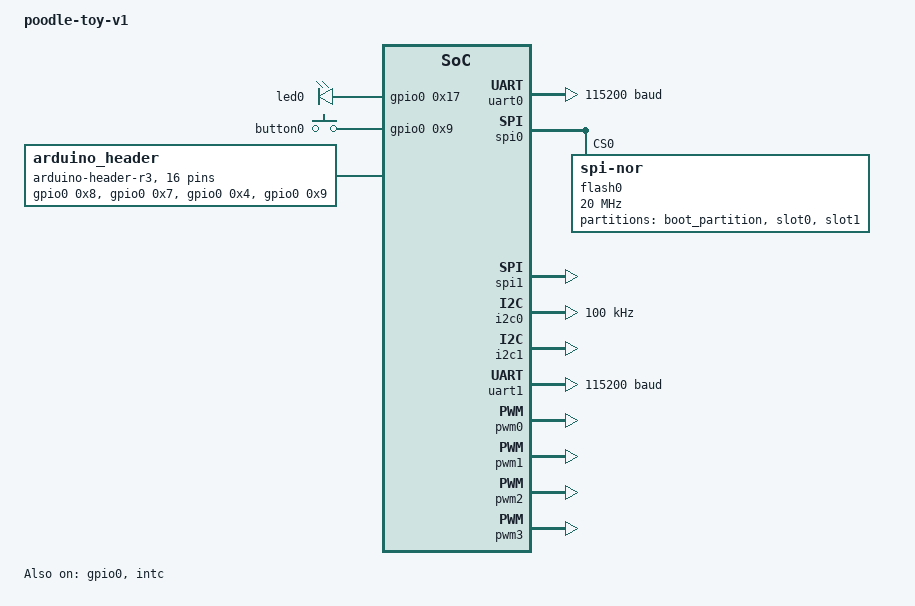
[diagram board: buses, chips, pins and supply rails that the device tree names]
/dts-v1/;

/* node '/' defined in zephyr/dts/riscv/caninos/puppy.dtsi:5 */
/ {
	#address-cells = < 0x1 >;             /* in zephyr/dts/riscv/caninos/puppy.dtsi:6 */
	#size-cells = < 0x1 >;                /* in zephyr/dts/riscv/caninos/puppy.dtsi:7 */
	model = "poodle-toy-v1";              /* in zephyr/boards/caninos/poodle-toy-v1/poodle-toy-v1.dts:5 */
	compatible = "caninos,poodle-toy-v1"; /* in zephyr/boards/caninos/poodle-toy-v1/poodle-toy-v1.dts:6 */

	/* node '/cpus' defined in zephyr/dts/riscv/caninos/puppy.dtsi:10 */
	cpus {
		#address-cells = < 0x1 >; /* in zephyr/dts/riscv/caninos/puppy.dtsi:11 */
		#size-cells = < 0x0 >;    /* in zephyr/dts/riscv/caninos/puppy.dtsi:12 */

		/* node '/cpus/cpu@0' defined in zephyr/dts/riscv/caninos/puppy.dtsi:14 */
		cpu@0 {
			device_type = "cpu";          /* in zephyr/dts/riscv/caninos/puppy.dtsi:15 */
			status = "okay";              /* in zephyr/dts/riscv/caninos/puppy.dtsi:16 */
			compatible = "riscv";         /* in zephyr/dts/riscv/caninos/puppy.dtsi:17 */
			riscv,isa = "rv32imfc_zicsr"; /* in zephyr/dts/riscv/caninos/puppy.dtsi:18 */
			reg = < 0x0 >;                /* in zephyr/dts/riscv/caninos/puppy.dtsi:19 */
		};
	};

	/* node '/soc' defined in zephyr/dts/riscv/caninos/puppy.dtsi:23 */
	soc: soc {
		#address-cells = < 0x1 >; /* in zephyr/dts/riscv/caninos/puppy.dtsi:24 */
		#size-cells = < 0x1 >;    /* in zephyr/dts/riscv/caninos/puppy.dtsi:25 */

		/* node '/soc/bootram@1c000000' defined in zephyr/dts/riscv/caninos/puppy.dtsi:27 */
		bootram: bootram@1c000000 {
			device_type = "memory";       /* in zephyr/dts/riscv/caninos/puppy.dtsi:28 */
			reg = < 0x1c000000 0x10000 >; /* in zephyr/dts/riscv/caninos/puppy.dtsi:29 */
			status = "okay";              /* in zephyr/dts/riscv/caninos/puppy.dtsi:30 */
		};

		/* node '/soc/sram@1c010000' defined in zephyr/dts/riscv/caninos/puppy.dtsi:33 */
		sram: sram@1c010000 {
			device_type = "memory";       /* in zephyr/dts/riscv/caninos/puppy.dtsi:34 */
			reg = < 0x1c010000 0x40000 >; /* in zephyr/dts/riscv/caninos/puppy.dtsi:35 */
			status = "okay";              /* in zephyr/dts/riscv/caninos/puppy.dtsi:36 */
		};

		/* node '/soc/gpio@1a101000' defined in zephyr/dts/riscv/caninos/puppy.dtsi:39 */
		gpio0: gpio@1a101000 {
			compatible = "caninos,puppy-gpio"; /* in zephyr/dts/riscv/caninos/puppy.dtsi:40 */
			gpio-controller;                   /* in zephyr/dts/riscv/caninos/puppy.dtsi:41 */
			ngpios = < 0x20 >;                 /* in zephyr/dts/riscv/caninos/puppy.dtsi:42 */
			reg = < 0x1a101000 0x1000 >;       /* in zephyr/dts/riscv/caninos/puppy.dtsi:43 */
			interrupts = < 0xf >;              /* in zephyr/dts/riscv/caninos/puppy.dtsi:44 */
			interrupt-parent = < &intc >;      /* in zephyr/dts/riscv/caninos/puppy.dtsi:45 */
			#gpio-cells = < 0x2 >;             /* in zephyr/dts/riscv/caninos/puppy.dtsi:46 */
			status = "okay";                   /* in zephyr/boards/caninos/poodle-toy-v1/poodle-toy-v1.dts:73 */
			phandle = < 0x2 >;                 /* in zephyr/boards/caninos/poodle-toy-v1/poodle-toy-v1.dts:29 */
		};

		/* node '/soc/interrupt-controller@1a109000' defined in zephyr/dts/riscv/caninos/puppy.dtsi:49 */
		intc: interrupt-controller@1a109000 {
			#interrupt-cells = < 0x1 >;              /* in zephyr/dts/riscv/caninos/puppy.dtsi:50 */
			compatible = "caninos,puppy-event-unit"; /* in zephyr/dts/riscv/caninos/puppy.dtsi:51 */
			interrupt-controller;                    /* in zephyr/dts/riscv/caninos/puppy.dtsi:52 */
			reg = < 0x1a109000 0x1000 >;             /* in zephyr/dts/riscv/caninos/puppy.dtsi:53 */
			status = "okay";                         /* in zephyr/boards/caninos/poodle-toy-v1/poodle-toy-v1.dts:69 */
			phandle = < 0x1 >;                       /* in zephyr/dts/riscv/caninos/puppy.dtsi:45 */
		};

		/* node '/soc/timer@1a10b000' defined in zephyr/dts/riscv/caninos/puppy.dtsi:56 */
		timer: timer@1a10b000 {
			compatible = "caninos,puppy-timer"; /* in zephyr/dts/riscv/caninos/puppy.dtsi:57 */
			reg = < 0x1a10b000 0x1000 >;        /* in zephyr/dts/riscv/caninos/puppy.dtsi:58 */
			interrupts = < 0xa >;               /* in zephyr/dts/riscv/caninos/puppy.dtsi:59 */
			interrupt-parent = < &intc >;       /* in zephyr/dts/riscv/caninos/puppy.dtsi:60 */
		};

		/* node '/soc/uart@1a102080' defined in zephyr/dts/riscv/caninos/puppy_v2.dtsi:4 */
		uart0: uart@1a102080 {
			compatible = "caninos,puppy-uart"; /* in zephyr/dts/riscv/caninos/puppy_v2.dtsi:5 */
			uart-controller;                   /* in zephyr/dts/riscv/caninos/puppy_v2.dtsi:6 */
			reg = < 0x1a102080 0x54 >;         /* in zephyr/dts/riscv/caninos/puppy_v2.dtsi:7 */
			uart-id = < 0x0 >;                 /* in zephyr/dts/riscv/caninos/puppy_v2.dtsi:8 */
			status = "okay";                   /* in zephyr/boards/caninos/poodle-toy-v1/poodle-toy-v1.dts:90 */
			current-speed = < 0x1c200 >;       /* in zephyr/boards/caninos/poodle-toy-v1/poodle-toy-v1.dts:91 */
			parity = "none";                   /* in zephyr/boards/caninos/poodle-toy-v1/poodle-toy-v1.dts:92 */
		};

		/* node '/soc/spi@1a102100' defined in zephyr/dts/riscv/caninos/puppy_v2.dtsi:11 */
		spi0: spi@1a102100 {
			compatible = "caninos,puppy-spi"; /* in zephyr/dts/riscv/caninos/puppy_v2.dtsi:12 */
			#address-cells = < 0x1 >;         /* in zephyr/dts/riscv/caninos/puppy_v2.dtsi:13 */
			#size-cells = < 0x0 >;            /* in zephyr/dts/riscv/caninos/puppy_v2.dtsi:14 */
			reg = < 0x1a102100 0x28 >;        /* in zephyr/dts/riscv/caninos/puppy_v2.dtsi:15 */
			spi-id = < 0x0 >;                 /* in zephyr/dts/riscv/caninos/puppy_v2.dtsi:16 */
			status = "okay";                  /* in zephyr/boards/caninos/poodle-toy-v1/poodle-toy-v1.dts:102 */

			/* node '/soc/spi@1a102100/flash@0' defined in bootloader/mcuboot/boot/zephyr/boards/poodle-toy-v1_puppy_v2.overlay:11 */
			flash0: flash@0 {
				compatible = "jedec,spi-nor";      /* in bootloader/mcuboot/boot/zephyr/boards/poodle-toy-v1_puppy_v2.overlay:12 */
				reg = < 0x0 >;                     /* in bootloader/mcuboot/boot/zephyr/boards/poodle-toy-v1_puppy_v2.overlay:13 */
				spi-max-frequency = < 0x1312d00 >; /* in bootloader/mcuboot/boot/zephyr/boards/poodle-toy-v1_puppy_v2.overlay:14 */
				size = < 0x800000 >;               /* in bootloader/mcuboot/boot/zephyr/boards/poodle-toy-v1_puppy_v2.overlay:15 */
				status = "okay";                   /* in bootloader/mcuboot/boot/zephyr/boards/poodle-toy-v1_puppy_v2.overlay:16 */

				/* node '/soc/spi@1a102100/flash@0/partitions' defined in bootloader/mcuboot/boot/zephyr/boards/poodle-toy-v1_puppy_v2.overlay:18 */
				partitions {
					compatible = "fixed-partitions"; /* in bootloader/mcuboot/boot/zephyr/boards/poodle-toy-v1_puppy_v2.overlay:19 */
					#size-cells = < 0x1 >;           /* in bootloader/mcuboot/boot/zephyr/boards/poodle-toy-v1_puppy_v2.overlay:20 */
					#address-cells = < 0x1 >;        /* in bootloader/mcuboot/boot/zephyr/boards/poodle-toy-v1_puppy_v2.overlay:21 */

					/* node '/soc/spi@1a102100/flash@0/partitions/partition@0' defined in bootloader/mcuboot/boot/zephyr/boards/poodle-toy-v1_puppy_v2.overlay:23 */
					boot_partition: partition@0 {
						reg = < 0x0 0x20000 >;    /* in bootloader/mcuboot/boot/zephyr/boards/poodle-toy-v1_puppy_v2.overlay:24 */
						label = "boot_partition"; /* in bootloader/mcuboot/boot/zephyr/boards/poodle-toy-v1_puppy_v2.overlay:25 */
						read-only;                /* in bootloader/mcuboot/boot/zephyr/boards/poodle-toy-v1_puppy_v2.overlay:26 */
					};

					/* node '/soc/spi@1a102100/flash@0/partitions/partition@20000' defined in bootloader/mcuboot/boot/zephyr/boards/poodle-toy-v1_puppy_v2.overlay:29 */
					slot0_partition: partition@20000 {
						reg = < 0x20000 0x40000 >; /* in bootloader/mcuboot/boot/zephyr/boards/poodle-toy-v1_puppy_v2.overlay:30 */
						label = "slot0";           /* in bootloader/mcuboot/boot/zephyr/boards/poodle-toy-v1_puppy_v2.overlay:31 */
					};

					/* node '/soc/spi@1a102100/flash@0/partitions/partition@60000' defined in bootloader/mcuboot/boot/zephyr/boards/poodle-toy-v1_puppy_v2.overlay:34 */
					slot1_partition: partition@60000 {
						reg = < 0x60000 0x40000 >; /* in bootloader/mcuboot/boot/zephyr/boards/poodle-toy-v1_puppy_v2.overlay:35 */
						label = "slot1";           /* in bootloader/mcuboot/boot/zephyr/boards/poodle-toy-v1_puppy_v2.overlay:36 */
					};
				};
			};
		};

		/* node '/soc/spi@1a102180' defined in zephyr/dts/riscv/caninos/puppy_v2.dtsi:19 */
		spi1: spi@1a102180 {
			compatible = "caninos,puppy-spi"; /* in zephyr/dts/riscv/caninos/puppy_v2.dtsi:20 */
			#address-cells = < 0x1 >;         /* in zephyr/dts/riscv/caninos/puppy_v2.dtsi:21 */
			#size-cells = < 0x0 >;            /* in zephyr/dts/riscv/caninos/puppy_v2.dtsi:22 */
			reg = < 0x1a102180 0x28 >;        /* in zephyr/dts/riscv/caninos/puppy_v2.dtsi:23 */
			spi-id = < 0x1 >;                 /* in zephyr/dts/riscv/caninos/puppy_v2.dtsi:24 */
		};

		/* node '/soc/i2c@1a102200' defined in zephyr/dts/riscv/caninos/puppy_v2.dtsi:27 */
		i2c0: i2c@1a102200 {
			compatible = "caninos,puppy-i2c"; /* in zephyr/dts/riscv/caninos/puppy_v2.dtsi:28 */
			#address-cells = < 0x1 >;         /* in zephyr/dts/riscv/caninos/puppy_v2.dtsi:29 */
			#size-cells = < 0x0 >;            /* in zephyr/dts/riscv/caninos/puppy_v2.dtsi:30 */
			reg = < 0x1a102200 0x34 >;        /* in zephyr/dts/riscv/caninos/puppy_v2.dtsi:31 */
			i2c-id = < 0x0 >;                 /* in zephyr/dts/riscv/caninos/puppy_v2.dtsi:32 */
			status = "okay";                  /* in zephyr/boards/caninos/poodle-toy-v1/poodle-toy-v1.dts:136 */
			clock-frequency = < 0x186a0 >;    /* in zephyr/boards/caninos/poodle-toy-v1/poodle-toy-v1.dts:137 */
		};

		/* node '/soc/i2c@1a102280' defined in zephyr/dts/riscv/caninos/puppy_v2.dtsi:35 */
		i2c1: i2c@1a102280 {
			compatible = "caninos,puppy-i2c"; /* in zephyr/dts/riscv/caninos/puppy_v2.dtsi:36 */
			#address-cells = < 0x1 >;         /* in zephyr/dts/riscv/caninos/puppy_v2.dtsi:37 */
			#size-cells = < 0x0 >;            /* in zephyr/dts/riscv/caninos/puppy_v2.dtsi:38 */
			reg = < 0x1a102280 0x34 >;        /* in zephyr/dts/riscv/caninos/puppy_v2.dtsi:39 */
			i2c-id = < 0x1 >;                 /* in zephyr/dts/riscv/caninos/puppy_v2.dtsi:40 */
		};

		/* node '/soc/uart@1a102480' defined in zephyr/dts/riscv/caninos/puppy_v2.dtsi:43 */
		uart1: uart@1a102480 {
			compatible = "caninos,puppy-uart"; /* in zephyr/dts/riscv/caninos/puppy_v2.dtsi:44 */
			uart-controller;                   /* in zephyr/dts/riscv/caninos/puppy_v2.dtsi:45 */
			reg = < 0x1a102480 0x54 >;         /* in zephyr/dts/riscv/caninos/puppy_v2.dtsi:46 */
			uart-id = < 0x1 >;                 /* in zephyr/dts/riscv/caninos/puppy_v2.dtsi:47 */
			status = "okay";                   /* in zephyr/boards/caninos/poodle-toy-v1/poodle-toy-v1.dts:96 */
			current-speed = < 0x1c200 >;       /* in zephyr/boards/caninos/poodle-toy-v1/poodle-toy-v1.dts:97 */
			parity = "none";                   /* in zephyr/boards/caninos/poodle-toy-v1/poodle-toy-v1.dts:98 */
		};

		/* node '/soc/pwm0@1a105000' defined in zephyr/dts/riscv/caninos/puppy_v2.dtsi:50 */
		pwm0: pwm0@1a105000 {
			compatible = "caninos,puppy-pwm"; /* in zephyr/dts/riscv/caninos/puppy_v2.dtsi:51 */
			reg = < 0x1a105000 0x40 >;        /* in zephyr/dts/riscv/caninos/puppy_v2.dtsi:52 */
			pwm-id = < 0x0 >;                 /* in zephyr/dts/riscv/caninos/puppy_v2.dtsi:53 */
			#pwm-cells = < 0x3 >;             /* in zephyr/dts/riscv/caninos/puppy_v2.dtsi:54 */
		};

		/* node '/soc/pwm1@1a105040' defined in zephyr/dts/riscv/caninos/puppy_v2.dtsi:57 */
		pwm1: pwm1@1a105040 {
			compatible = "caninos,puppy-pwm"; /* in zephyr/dts/riscv/caninos/puppy_v2.dtsi:58 */
			reg = < 0x1a105040 0x40 >;        /* in zephyr/dts/riscv/caninos/puppy_v2.dtsi:59 */
			pwm-id = < 0x1 >;                 /* in zephyr/dts/riscv/caninos/puppy_v2.dtsi:60 */
			#pwm-cells = < 0x3 >;             /* in zephyr/dts/riscv/caninos/puppy_v2.dtsi:61 */
			status = "okay";                  /* in zephyr/boards/caninos/poodle-toy-v1/poodle-toy-v1.dts:77 */
		};

		/* node '/soc/pwm2@1a105080' defined in zephyr/dts/riscv/caninos/puppy_v2.dtsi:64 */
		pwm2: pwm2@1a105080 {
			compatible = "caninos,puppy-pwm"; /* in zephyr/dts/riscv/caninos/puppy_v2.dtsi:65 */
			reg = < 0x1a105080 0x40 >;        /* in zephyr/dts/riscv/caninos/puppy_v2.dtsi:66 */
			pwm-id = < 0x2 >;                 /* in zephyr/dts/riscv/caninos/puppy_v2.dtsi:67 */
			#pwm-cells = < 0x3 >;             /* in zephyr/dts/riscv/caninos/puppy_v2.dtsi:68 */
			status = "okay";                  /* in zephyr/boards/caninos/poodle-toy-v1/poodle-toy-v1.dts:81 */
		};

		/* node '/soc/pwm3@1a1050c0' defined in zephyr/dts/riscv/caninos/puppy_v2.dtsi:71 */
		pwm3: pwm3@1a1050c0 {
			compatible = "caninos,puppy-pwm"; /* in zephyr/dts/riscv/caninos/puppy_v2.dtsi:72 */
			reg = < 0x1a1050c0 0x40 >;        /* in zephyr/dts/riscv/caninos/puppy_v2.dtsi:73 */
			pwm-id = < 0x3 >;                 /* in zephyr/dts/riscv/caninos/puppy_v2.dtsi:74 */
			#pwm-cells = < 0x3 >;             /* in zephyr/dts/riscv/caninos/puppy_v2.dtsi:75 */
			status = "okay";                  /* in zephyr/boards/caninos/poodle-toy-v1/poodle-toy-v1.dts:85 */
		};
	};

	/* node '/chosen' defined in zephyr/boards/caninos/poodle-toy-v1/poodle-toy-v1.dts:8 */
	chosen {
		zephyr,code-partition = &slot0_partition; /* in zephyr/boards/caninos/poodle-toy-v1/poodle-toy-v1.dts:10 */
		zephyr,flash-controller = &spi0;          /* in zephyr/boards/caninos/poodle-toy-v1/poodle-toy-v1.dts:11 */
		zephyr,flash = &flash0;                   /* in zephyr/boards/caninos/poodle-toy-v1/poodle-toy-v1.dts:13 */
		zephyr,console = &uart0;                  /* in zephyr/boards/caninos/poodle-toy-v1/poodle-toy-v1.dts:14 */
		zephyr,shell-uart = &uart0;               /* in zephyr/boards/caninos/poodle-toy-v1/poodle-toy-v1.dts:15 */
		mcuboot,ram-load-dev = &sram;             /* in bootloader/mcuboot/boot/zephyr/boards/poodle-toy-v1_puppy_v2.overlay:5 */
		zephyr,sram = &bootram;                   /* in bootloader/mcuboot/boot/zephyr/boards/poodle-toy-v1_puppy_v2.overlay:6 */
	};

	/* node '/aliases' defined in zephyr/boards/caninos/poodle-toy-v1/poodle-toy-v1.dts:18 */
	aliases {
		led0 = &led0;               /* in zephyr/boards/caninos/poodle-toy-v1/poodle-toy-v1.dts:19 */
		mcuboot-led0 = &led0;       /* in zephyr/boards/caninos/poodle-toy-v1/poodle-toy-v1.dts:20 */
		mcuboot-button0 = &button0; /* in zephyr/boards/caninos/poodle-toy-v1/poodle-toy-v1.dts:21 */
		eeprom-0 = &flash0;         /* in zephyr/boards/caninos/poodle-toy-v1/poodle-toy-v1.dts:22 */
	};

	/* node '/leds' defined in zephyr/boards/caninos/poodle-toy-v1/poodle-toy-v1.dts:25 */
	leds {
		compatible = "gpio-leds"; /* in zephyr/boards/caninos/poodle-toy-v1/poodle-toy-v1.dts:26 */

		/* node '/leds/led_0' defined in zephyr/boards/caninos/poodle-toy-v1/poodle-toy-v1.dts:28 */
		led0: led_0 {
			gpios = < &gpio0 0x17 0x0 >; /* in zephyr/boards/caninos/poodle-toy-v1/poodle-toy-v1.dts:29 */
			label = "led0";              /* in zephyr/boards/caninos/poodle-toy-v1/poodle-toy-v1.dts:30 */
		};
	};

	/* node '/buttons' defined in zephyr/boards/caninos/poodle-toy-v1/poodle-toy-v1.dts:34 */
	buttons {
		compatible = "gpio-keys"; /* in zephyr/boards/caninos/poodle-toy-v1/poodle-toy-v1.dts:35 */

		/* node '/buttons/button_0' defined in zephyr/boards/caninos/poodle-toy-v1/poodle-toy-v1.dts:37 */
		button0: button_0 {
			gpios = < &gpio0 0x9 0x0 >; /* in zephyr/boards/caninos/poodle-toy-v1/poodle-toy-v1.dts:38 */
			label = "button0";          /* in zephyr/boards/caninos/poodle-toy-v1/poodle-toy-v1.dts:39 */
		};
	};

	/* node '/connector' defined in zephyr/boards/caninos/poodle-toy-v1/poodle-toy-v1.dts:43 */
	arduino_header: connector {
		compatible = "arduino-header-r3";          /* in zephyr/boards/caninos/poodle-toy-v1/poodle-toy-v1.dts:44 */
		#gpio-cells = < 0x2 >;                     /* in zephyr/boards/caninos/poodle-toy-v1/poodle-toy-v1.dts:45 */
		gpio-map-mask = < 0xffffffff 0xffffffc0 >; /* in zephyr/boards/caninos/poodle-toy-v1/poodle-toy-v1.dts:46 */
		gpio-map-pass-thru = < 0x0 0x3f >;         /* in zephyr/boards/caninos/poodle-toy-v1/poodle-toy-v1.dts:47 */
		gpio-map = < 0x6 0x0 &gpio0 0x8 0x0 >,
		           < 0x7 0x0 &gpio0 0x7 0x0 >,
		           < 0x8 0x0 &gpio0 0x4 0x0 >,
		           < 0x9 0x0 &gpio0 0x9 0x0 >,
		           < 0xa 0x0 &gpio0 0x18 0x0 >,
		           < 0xb 0x0 &gpio0 0xa 0x0 >,
		           < 0xc 0x0 &gpio0 0xb 0x0 >,
		           < 0xd 0x0 &gpio0 0xc 0x0 >,
		           < 0xe 0x0 &gpio0 0xd 0x0 >,
		           < 0xf 0x0 &gpio0 0xe 0x0 >,
		           < 0x10 0x0 &gpio0 0x5 0x0 >,
		           < 0x11 0x0 &gpio0 0x0 0x0 >,
		           < 0x12 0x0 &gpio0 0x1 0x0 >,
		           < 0x13 0x0 &gpio0 0x6 0x0 >,
		           < 0x14 0x0 &gpio0 0x1a 0x0 >,
		           < 0x15 0x0 &gpio0 0x1b 0x0 >;   /* in zephyr/boards/caninos/poodle-toy-v1/poodle-toy-v1.dts:48 */
	};
};
